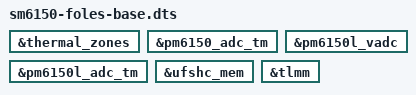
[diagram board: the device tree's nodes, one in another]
/* Copyright (c) 2018, The Linux Foundation. All rights reserved.
 *
 * This program is free software; you can redistribute it and/or modify
 * it under the terms of the GNU General Public License version 2 and
 * only version 2 as published by the Free Software Foundation.
 *
 * This program is distributed in the hope that it will be useful,
 * but WITHOUT ANY WARRANTY; without even the implied warranty of
 * MERCHANTABILITY or FITNESS FOR A PARTICULAR PURPOSE.  See the
 * GNU General Public License for more details.
 */

/dts-v1/;

#include "sm6150-moto-base.dtsi"

&thermal_zones {
	/delete-node/ rf_pa0_therm-therm;
	/delete-node/ quiet-therm;
	/delete-node/ emmc_ufs-therm;
	/delete-node/ xo-therm-adc;
	/delete-node/ sdm-therm;
	/delete-node/ conn-therm;
	/delete-node/ xo-therm;
};

&pm6150_adc_tm {
	/delete-node/ io-channels;
};

&pm6150l_vadc {
	/delete-node/ emmc_ufs_therm;
	/delete-node/ rf_pa0_therm;
};


&pm6150l_adc_tm {
	/delete-node/ emmc_ufs_therm;
	/delete-node/ rf_pa0_therm;
};

&ufshc_mem {
	/delete-property/ spm-level;
};

&tlmm {
	/delete-node/ nfc;
};
